VERSION ""

NS_ :

BS_:

BU_:

BO_ 0 aerl_earthguard_information: 8 Vector__XXX
	SG_ serial_number : 32|32@1+ (1,0) [0|4294967295] "#" Vector__XXX
	SG_ status : 0|32@1+ (1,0) [0|4294967295] "" Vector__XXX

BO_ 1 aerl_earthguard_voltage: 8 Vector__XXX
	SG_ pv1 : 32|32@1+ (0.001,0) [0|4294967295] "V" Vector__XXX
	SG_ pv2 : 0|32@1+ (0.001,0) [0|4294967295] "V" Vector__XXX

BO_ 2 aerl_earthguard_pv1_resistance: 8 Vector__XXX
	SG_ positive : 32|32@1+ (1000,0) [0|4294967295] "Ohm" Vector__XXX
	SG_ negative : 0|32@1+ (1000,0) [0|4294967295] "Ohm" Vector__XXX

BO_ 3 aerl_earthguard_pv2_resistance: 8 Vector__XXX
	SG_ positive : 32|32@1+ (1000,0) [0|4294967295] "Ohm" Vector__XXX
	SG_ negative : 0|32@1+ (1000,0) [0|4294967295] "Ohm" Vector__XXX

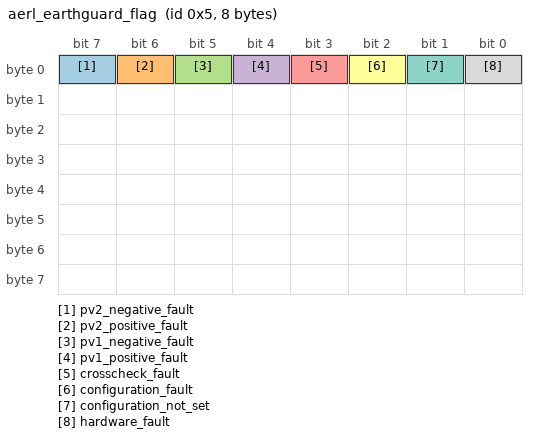
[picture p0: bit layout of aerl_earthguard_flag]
BO_ 5 aerl_earthguard_flag: 8 Vector__XXX
	SG_ pv2_negative_fault : 7|1@1+ (1,0) [0|1] "Boolean" Vector__XXX
	SG_ pv2_positive_fault : 6|1@1+ (1,0) [0|1] "Boolean" Vector__XXX
	SG_ pv1_negative_fault : 5|1@1+ (1,0) [0|1] "Boolean" Vector__XXX
	SG_ pv1_positive_fault : 4|1@1+ (1,0) [0|1] "Boolean" Vector__XXX
	SG_ crosscheck_fault : 3|1@1+ (1,0) [0|1] "Boolean" Vector__XXX
	SG_ configuration_fault : 2|1@1+ (1,0) [0|1] "Boolean" Vector__XXX
	SG_ configuration_not_set : 1|1@1+ (1,0) [0|1] "Boolean" Vector__XXX
	SG_ hardware_fault : 0|1@1+ (1,0) [0|1] "Boolean" Vector__XXX

BO_ 35 aerl_earthguard_reset: 0 Vector__XXX

CM_ SG_ 0 serial_number "Device serial number, allocated at manufacture.";
CM_ SG_ 1 pv1 "PV array 1 voltage.";
CM_ SG_ 1 pv2 "PV array 2 voltage.";
CM_ SG_ 2 positive "PV 1 positive resistance to earth.";
CM_ SG_ 2 negative "PV 1 negative resistance to earth.";
CM_ SG_ 3 positive "PV 2 positive resistance to earth.";
CM_ SG_ 3 negative "PV 2 negative resistance to earth.";
CM_ SG_ 5 pv2_negative_fault "PV 2 negative fault.";
CM_ SG_ 5 pv2_positive_fault "PV 2 positive fault.";
CM_ SG_ 5 pv1_negative_fault "PV 1 negative fault.";
CM_ SG_ 5 pv1_positive_fault "PV 1 positive fault.";
CM_ SG_ 5 crosscheck_fault "Cross-check fault.";
CM_ SG_ 5 configuration_fault "Bad configuration.";
CM_ SG_ 5 configuration_not_set "Configuration not set.";
CM_ SG_ 5 hardware_fault "Hardware fault.";

VAL_ 0 status 0 "Normal";
